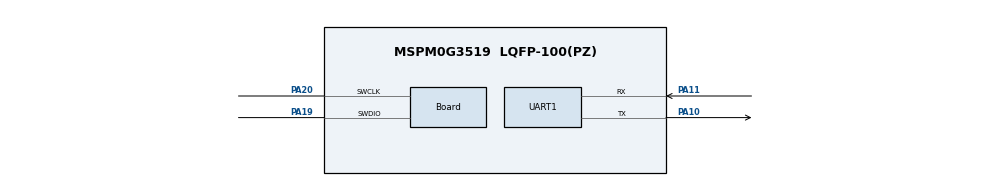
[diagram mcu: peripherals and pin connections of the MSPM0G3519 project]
/**
 * These arguments were used when this file was generated. They will be automatically applied on subsequent loads
 * via the GUI or CLI. Run CLI with '--help' for additional information on how to override these arguments.
 * @cliArgs --device "MSPM0G351X" --part "Default" --package "LQFP-100(PZ)" --product "mspm0_sdk@2.09.00.02"
 * @v2CliArgs --device "MSPM0G3519" --package "LQFP-100(PZ)" --product "mspm0_sdk@2.09.00.02"
 * @versions {"tool":"1.25.0+4268"}
 */

/**
 * Import the modules used in this configuration.
 */
const Board         = scripting.addModule("/ti/driverlib/Board");
const DMA           = scripting.addModule("/ti/driverlib/DMA");
const SYSCTL        = scripting.addModule("/ti/driverlib/SYSCTL");
const UART          = scripting.addModule("/ti/driverlib/UART", {}, false);
const UART1         = UART.addInstance();
const ProjectConfig = scripting.addModule("/ti/project_config/ProjectConfig");

/**
 * Write custom configuration values to the imported modules.
 */
Board.peripheral.$assign          = "DEBUGSS";
Board.peripheral.swclkPin.$assign = "PA20";
Board.peripheral.swdioPin.$assign = "PA19";

SYSCTL.forceDefaultClkConfig = true;
SYSCTL.clockTreeEn           = true;

UART1.$name                             = "UART_SHELL";
UART1.targetBaudRate                    = 128000;
UART1.enabledInterrupts                 = ["RX","TX"];
UART1.enabledDMARXTriggers              = "DL_UART_DMA_INTERRUPT_RX";
UART1.enabledDMATXTriggers              = "DL_UART_DMA_INTERRUPT_TX";
UART1.analogGlitchFilter                = "DL_UART_PULSE_WIDTH_10_NS";
UART1.peripheral.rxPin.$assign          = "PA11";
UART1.peripheral.txPin.$assign          = "PA10";
UART1.txPinConfig.$name                 = "ti_driverlib_gpio_GPIOPinGeneric0";
UART1.txPinConfig.direction             = scripting.forceWrite("OUTPUT");
UART1.txPinConfig.hideOutputInversion   = scripting.forceWrite(false);
UART1.txPinConfig.onlyInternalResistor  = scripting.forceWrite(false);
UART1.txPinConfig.passedPeripheralType  = scripting.forceWrite("Digital");
UART1.rxPinConfig.$name                 = "ti_driverlib_gpio_GPIOPinGeneric1";
UART1.rxPinConfig.hideOutputInversion   = scripting.forceWrite(false);
UART1.rxPinConfig.onlyInternalResistor  = scripting.forceWrite(false);
UART1.rxPinConfig.passedPeripheralType  = scripting.forceWrite("Digital");
UART1.DMA_CHANNEL_RX.addressMode        = "f2b";
UART1.DMA_CHANNEL_RX.srcLength          = "BYTE";
UART1.DMA_CHANNEL_RX.dstLength          = "BYTE";
UART1.DMA_CHANNEL_RX.$name              = "DMA_CH1";
UART1.DMA_CHANNEL_RX.peripheral.$assign = "DMA_CH1";
UART1.DMA_CHANNEL_TX.addressMode        = "b2f";
UART1.DMA_CHANNEL_TX.srcLength          = "BYTE";
UART1.DMA_CHANNEL_TX.dstLength          = "BYTE";
UART1.DMA_CHANNEL_TX.$name              = "DMA_CH0";

ProjectConfig.migrationCondition = true;
ProjectConfig.genLibDrivers      = true;

/**
 * Pinmux solution for unlocked pins/peripherals. This ensures that minor changes to the automatic solver in a future
 * version of the tool will not impact the pinmux you originally saw.  These lines can be completely deleted in order to
 * re-solve from scratch.
 */
UART1.peripheral.$suggestSolution                = "UART0";
UART1.DMA_CHANNEL_TX.peripheral.$suggestSolution = "DMA_CH0";
